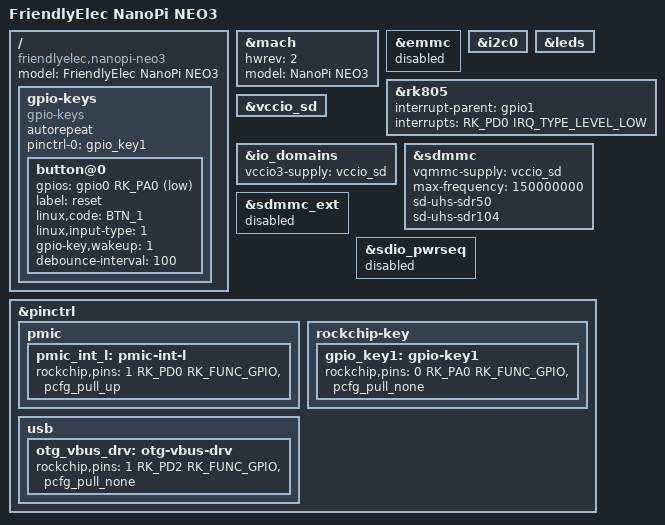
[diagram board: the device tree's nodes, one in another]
// SPDX-License-Identifier: (GPL-2.0+ OR MIT)
/*
 * Copyright (c) 2020 FriendlyElec Computer Tech. Co., Ltd.
 * (http://www.friendlyarm.com)
 */

/dts-v1/;
#include <dt-bindings/input/linux-event-codes.h>
#include "rk3328-nanopi-r2-common.dtsi"

/ {
	model = "FriendlyElec NanoPi NEO3";
	compatible = "friendlyelec,nanopi-neo3", "rockchip,rk3328";

	gpio-keys {
		compatible = "gpio-keys";
		#address-cells = <1>;
		#size-cells = <0>;
		autorepeat;

		pinctrl-names = "default";
		pinctrl-0 = <&gpio_key1>;

		button@0 {
			gpios = <&gpio0 RK_PA0 GPIO_ACTIVE_LOW>;
			label = "reset";
			linux,code = <BTN_1>;
			linux,input-type = <1>;
			gpio-key,wakeup = <1>;
			debounce-interval = <100>;
		};
	};
};

&mach {
	hwrev = <2>;
	model = "NanoPi NEO3";
};

&emmc {
	status = "disabled";
};

&i2c0 {
	status = "okay";
};

&leds {
	status = "okay";
};

&rk805 {
	interrupt-parent = <&gpio1>;
	interrupts = <RK_PD0 IRQ_TYPE_LEVEL_LOW>;
};

&vccio_sd {
	status = "okay";
};

&io_domains {
	vccio3-supply = <&vccio_sd>;
};

&sdmmc {
	vqmmc-supply = <&vccio_sd>;
	max-frequency = <150000000>;
	sd-uhs-sdr50;
	sd-uhs-sdr104;
	status = "okay";
};

&sdmmc_ext {
	status = "disabled";
};

&sdio_pwrseq {
	status = "disabled";
};

&pinctrl {
	pmic {
		pmic_int_l: pmic-int-l {
			rockchip,pins = <1 RK_PD0 RK_FUNC_GPIO &pcfg_pull_up>;
		};
	};

	rockchip-key {
		gpio_key1: gpio-key1 {
			rockchip,pins = <0 RK_PA0 RK_FUNC_GPIO &pcfg_pull_none>;
		};
	};

	usb {
		otg_vbus_drv: otg-vbus-drv {
			rockchip,pins = <1 RK_PD2 RK_FUNC_GPIO &pcfg_pull_none>;
		};
	};
};
